AUTOSAR XML (schema 4.0)
standard types defined: uint8, uint16
package /BCM_DataTypes
  7 x app type, all with category=VALUE:
    DoorStatusType: base-type=uint8
    LockStateType: base-type=uint8
    LightSwitchType: base-type=uint8
    LightOutputType: base-type=uint16
    WiperSpeedType: base-type=uint8
    WiperCtrlType: base-type=uint8
    PowerModeType: base-type=uint8
package /BCM_Interfaces
  7 x sender receiver interface:
    DoorStatus_IF
      data DoorStatus: type=DoorStatusType
    DoorLock_IF
      data LockCommand: type=LockStateType
    LightSwitch_IF
      data LightSwitch: type=LightSwitchType
    LightOutput_IF
      data LightOutput: type=LightOutputType
    WiperSpeed_IF
      data WiperSpeed: type=WiperSpeedType
    WiperCtrl_IF
      data WiperControl: type=WiperCtrlType
    PowerMode_IF
      data PowerMode: type=PowerModeType
package /BCM_Door
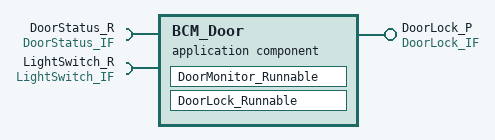
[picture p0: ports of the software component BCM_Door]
  application sw component type BCM_Door  # Body Control Module — Door Control SWC
    require port DoorStatus_R: required-interface=DoorStatus_IF
    provide port DoorLock_P: provided-interface=DoorLock_IF
    require port LightSwitch_R: required-interface=LightSwitch_IF
    behavior DoorBehavior
      runnable DoorMonitor_Runnable: symbol=BCM_Door_Monitor, minimum-start-interval=0.05
      runnable DoorLock_Runnable: symbol=BCM_Door_ProcessLock, minimum-start-interval=0.01
package /BCM_Light
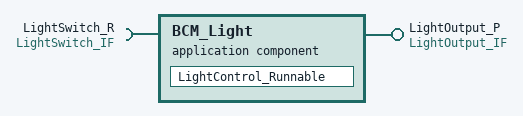
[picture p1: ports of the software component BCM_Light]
  application sw component type BCM_Light  # Body Control Module — Lighting Control SWC
    require port LightSwitch_R: required-interface=LightSwitch_IF
    provide port LightOutput_P: provided-interface=LightOutput_IF
    behavior LightBehavior
      runnable LightControl_Runnable: symbol=BCM_Light_Control, minimum-start-interval=0.02
package /BCM_Wiper
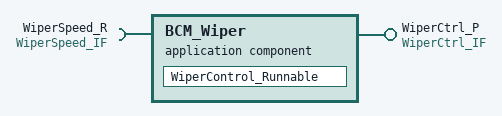
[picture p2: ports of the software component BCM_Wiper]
  application sw component type BCM_Wiper  # Body Control Module — Wiper Control SWC
    require port WiperSpeed_R: required-interface=WiperSpeed_IF
    provide port WiperCtrl_P: provided-interface=WiperCtrl_IF
    behavior WiperBehavior
      runnable WiperControl_Runnable: symbol=BCM_Wiper_Control, minimum-start-interval=0.02
package /BCM_Power
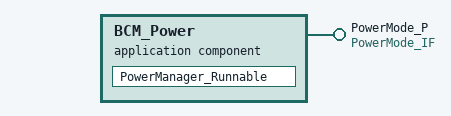
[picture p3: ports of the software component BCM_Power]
  application sw component type BCM_Power  # Body Control Module — Power Mode Management SWC
    provide port PowerMode_P: provided-interface=PowerMode_IF
    behavior PowerBehavior
      runnable PowerManager_Runnable: symbol=BCM_Power_Manager, minimum-start-interval=0.1
